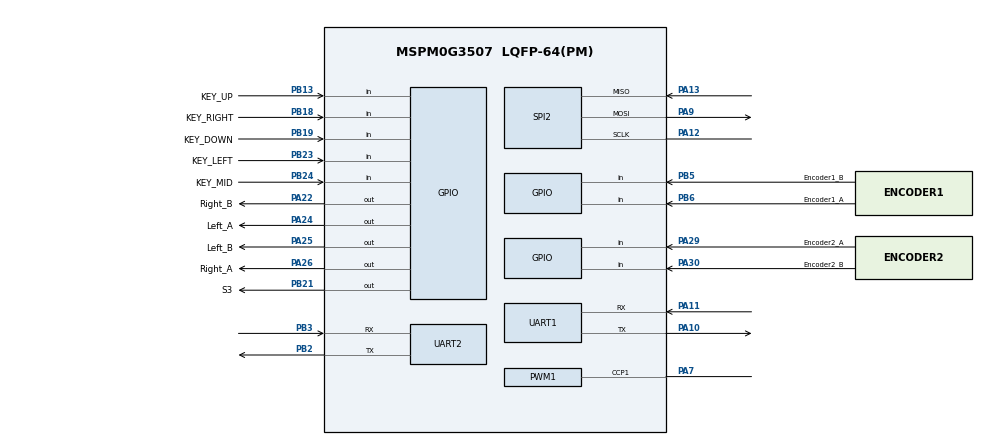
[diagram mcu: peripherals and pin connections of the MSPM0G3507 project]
/**
 * These arguments were used when this file was generated. They will be automatically applied on subsequent loads
 * via the GUI or CLI. Run CLI with '--help' for additional information on how to override these arguments.
 * @cliArgs --device "MSPM0G350X" --part "Default" --package "LQFP-64(PM)" --product "mspm0_sdk@2.02.00.05"
 * @v2CliArgs --device "MSPM0G3507" --package "LQFP-64(PM)" --product "mspm0_sdk@2.02.00.05"
 * @versions {"tool":"1.21.1+3772"}
 */

/**
 * Import the modules used in this configuration.
 */
const ADC12   = scripting.addModule("/ti/driverlib/ADC12", {}, false);
const ADC121  = ADC12.addInstance();
const GPIO    = scripting.addModule("/ti/driverlib/GPIO", {}, false);
const GPIO1   = GPIO.addInstance();
const GPIO2   = GPIO.addInstance();
const GPIO3   = GPIO.addInstance();
const GPIO4   = GPIO.addInstance();
const GPIO5   = GPIO.addInstance();
const GPIO6   = GPIO.addInstance();
const GPIO7   = GPIO.addInstance();
const GPIO8   = GPIO.addInstance();
const PWM     = scripting.addModule("/ti/driverlib/PWM", {}, false);
const PWM1    = PWM.addInstance();
const SPI     = scripting.addModule("/ti/driverlib/SPI", {}, false);
const SPI1    = SPI.addInstance();
const SPI2    = SPI.addInstance();
const SYSCTL  = scripting.addModule("/ti/driverlib/SYSCTL");
const SYSTICK = scripting.addModule("/ti/driverlib/SYSTICK");
const TIMER   = scripting.addModule("/ti/driverlib/TIMER", {}, false);
const TIMER1  = TIMER.addInstance();
const UART    = scripting.addModule("/ti/driverlib/UART", {}, false);
const UART1   = UART.addInstance();
const UART2   = UART.addInstance();
const UART3   = UART.addInstance();

/**
 * Write custom configuration values to the imported modules.
 */
const divider9       = system.clockTree["UDIV"];
divider9.divideValue = 2;

const gate7  = system.clockTree["MFCLKGATE"];
gate7.enable = true;

const multiplier2         = system.clockTree["PLL_QDIV"];
multiplier2.multiplyValue = 4;

const mux4       = system.clockTree["EXHFMUX"];
mux4.inputSelect = "EXHFMUX_XTAL";

const mux8       = system.clockTree["HSCLKMUX"];
mux8.inputSelect = "HSCLKMUX_SYSPLL0";

const mux12       = system.clockTree["SYSPLLMUX"];
mux12.inputSelect = "zSYSPLLMUX_HFCLK";

const pinFunction4       = system.clockTree["HFXT"];
pinFunction4.inputFreq   = 40;
pinFunction4.HFXTStartup = 10;
pinFunction4.enable      = true;

ADC121.$name                             = "ADC_track";
ADC121.sampClkDiv                        = "DL_ADC12_CLOCK_DIVIDE_8";
ADC121.repeatMode                        = true;
ADC121.peripheral.adcPin0.$assign        = "PA27";
ADC121.adcPin0Config.hideOutputInversion = scripting.forceWrite(false);
ADC121.adcPin0Config.$name               = "ti_driverlib_gpio_GPIOPinGeneric2";

const Board = scripting.addModule("/ti/driverlib/Board", {}, false);

GPIO1.$name                               = "KEY";
GPIO1.associatedPins.create(5);
GPIO1.associatedPins[0].internalResistor  = "PULL_UP";
GPIO1.associatedPins[0].interruptEn       = true;
GPIO1.associatedPins[0].direction         = "INPUT";
GPIO1.associatedPins[0].polarity          = "FALL";
GPIO1.associatedPins[0].$name             = "KEY_UP";
GPIO1.associatedPins[0].interruptPriority = "2";
GPIO1.associatedPins[0].pin.$assign       = "PB13";
GPIO1.associatedPins[1].direction         = "INPUT";
GPIO1.associatedPins[1].interruptEn       = true;
GPIO1.associatedPins[1].internalResistor  = "PULL_UP";
GPIO1.associatedPins[1].polarity          = "FALL";
GPIO1.associatedPins[1].$name             = "KEY_DOWN";
GPIO1.associatedPins[1].interruptPriority = "2";
GPIO1.associatedPins[1].pin.$assign       = "PB19";
GPIO1.associatedPins[2].$name             = "KEY_LEFT";
GPIO1.associatedPins[2].direction         = "INPUT";
GPIO1.associatedPins[2].interruptEn       = true;
GPIO1.associatedPins[2].polarity          = "FALL";
GPIO1.associatedPins[2].interruptPriority = "2";
GPIO1.associatedPins[2].pin.$assign       = "PB23";
GPIO1.associatedPins[3].$name             = "KEY_RIGHT";
GPIO1.associatedPins[3].direction         = "INPUT";
GPIO1.associatedPins[3].interruptEn       = true;
GPIO1.associatedPins[3].interruptPriority = "2";
GPIO1.associatedPins[3].polarity          = "FALL";
GPIO1.associatedPins[3].pin.$assign       = "PB18";
GPIO1.associatedPins[4].$name             = "KEY_MID";
GPIO1.associatedPins[4].direction         = "INPUT";
GPIO1.associatedPins[4].interruptEn       = true;
GPIO1.associatedPins[4].interruptPriority = "2";
GPIO1.associatedPins[4].polarity          = "FALL";
GPIO1.associatedPins[4].pin.$assign       = "PB24";

GPIO2.$name                          = "MOTOR_DIR";
GPIO2.associatedPins.create(4);
GPIO2.associatedPins[0].assignedPort = "PORTA";
GPIO2.associatedPins[0].assignedPin  = "24";
GPIO2.associatedPins[0].$name        = "Left_A";
GPIO2.associatedPins[0].initialValue = "SET";
GPIO2.associatedPins[0].pin.$assign  = "PA24";
GPIO2.associatedPins[1].$name        = "Left_B";
GPIO2.associatedPins[1].initialValue = "SET";
GPIO2.associatedPins[1].pin.$assign  = "PA25";
GPIO2.associatedPins[2].$name        = "Right_A";
GPIO2.associatedPins[2].initialValue = "SET";
GPIO2.associatedPins[2].pin.$assign  = "PA26";
GPIO2.associatedPins[3].$name        = "Right_B";
GPIO2.associatedPins[3].initialValue = "SET";
GPIO2.associatedPins[3].pin.$assign  = "PA22";

GPIO3.$name                          = "OLED";
GPIO3.port                           = "PORTB";
GPIO3.associatedPins.create(2);
GPIO3.associatedPins[0].$name        = "SCL";
GPIO3.associatedPins[0].initialValue = "SET";
GPIO3.associatedPins[0].assignedPin  = "9";
GPIO3.associatedPins[1].$name        = "SDA";
GPIO3.associatedPins[1].initialValue = "SET";
GPIO3.associatedPins[1].assignedPin  = "8";

GPIO4.$name                          = "TRACK";
GPIO4.associatedPins.create(3);
GPIO4.associatedPins[0].initialValue = "SET";
GPIO4.associatedPins[0].$name        = "S1";
GPIO4.associatedPins[1].initialValue = "SET";
GPIO4.associatedPins[1].$name        = "S2";
GPIO4.associatedPins[2].$name        = "S3";
GPIO4.associatedPins[2].pin.$assign  = "PB21";

GPIO5.$name                               = "Encoder";
GPIO5.associatedPins.create(4);
GPIO5.associatedPins[0].direction         = "INPUT";
GPIO5.associatedPins[0].interruptEn       = true;
GPIO5.associatedPins[0].polarity          = "RISE";
GPIO5.associatedPins[0].$name             = "Encoder1_A";
GPIO5.associatedPins[0].pin.$assign       = "PB6";
GPIO5.associatedPins[1].direction         = "INPUT";
GPIO5.associatedPins[1].interruptEn       = true;
GPIO5.associatedPins[1].polarity          = "RISE";
GPIO5.associatedPins[1].$name             = "Encoder1_B";
GPIO5.associatedPins[1].interruptPriority = "0";
GPIO5.associatedPins[1].pin.$assign       = "PB5";
GPIO5.associatedPins[2].$name             = "Encoder2_A";
GPIO5.associatedPins[2].direction         = "INPUT";
GPIO5.associatedPins[2].interruptEn       = true;
GPIO5.associatedPins[2].polarity          = "RISE";
GPIO5.associatedPins[2].interruptPriority = "0";
GPIO5.associatedPins[2].pin.$assign       = "PA29";
GPIO5.associatedPins[3].$name             = "Encoder2_B";
GPIO5.associatedPins[3].direction         = "INPUT";
GPIO5.associatedPins[3].interruptEn       = true;
GPIO5.associatedPins[3].polarity          = "RISE";
GPIO5.associatedPins[3].interruptPriority = "0";
GPIO5.associatedPins[3].pin.$assign       = "PA30";

GPIO6.$name                          = "IMU";
GPIO6.associatedPins.create(3);
GPIO6.associatedPins[0].initialValue = "SET";
GPIO6.associatedPins[0].$name        = "IMU_CS";
GPIO6.associatedPins[0].assignedPort = "PORTA";
GPIO6.associatedPins[0].assignedPin  = "8";
GPIO6.associatedPins[1].$name        = "INT1";
GPIO6.associatedPins[1].assignedPort = "PORTB";
GPIO6.associatedPins[1].assignedPin  = "7";
GPIO6.associatedPins[2].$name        = "INT2";
GPIO6.associatedPins[2].assignedPort = "PORTB";
GPIO6.associatedPins[2].assignedPin  = "4";

GPIO7.$name                   = "LCD";
GPIO7.associatedPins.create(3);
GPIO7.associatedPins[0].$name = "LCD_CS";
GPIO7.associatedPins[1].$name = "RST";
GPIO7.associatedPins[2].$name = "DC";

GPIO8.$name                          = "Beep";
GPIO8.associatedPins[0].$name        = "buzzer";
GPIO8.associatedPins[0].assignedPort = "PORTB";
GPIO8.associatedPins[0].assignedPin  = "12";

PWM1.timerStartTimer                    = true;
PWM1.pwmMode                            = "EDGE_ALIGN_UP";
PWM1.$name                              = "PWM_Motor";
PWM1.timerCount                         = 3200;
PWM1.ccIndex                            = [1,3];
PWM1.peripheral.ccp1Pin.$assign         = "PA7";
PWM1.ccp1PinConfig.direction            = scripting.forceWrite("OUTPUT");
PWM1.ccp1PinConfig.hideOutputInversion  = scripting.forceWrite(false);
PWM1.ccp1PinConfig.onlyInternalResistor = scripting.forceWrite(false);
PWM1.ccp1PinConfig.passedPeripheralType = scripting.forceWrite("Digital");
PWM1.ccp1PinConfig.$name                = "ti_driverlib_gpio_GPIOPinGeneric8";
PWM1.PWM_CHANNEL_3.$name                = "ti_driverlib_pwm_PWMTimerCC3";
PWM1.ccp3PinConfig.$name                = "ti_driverlib_gpio_GPIOPinGeneric14";
PWM1.PWM_CHANNEL_1.$name                = "ti_driverlib_pwm_PWMTimerCC0";

SPI1.$name                              = "SPI_LCD";
SPI1.targetBitRate                      = 32000000;
SPI1.frameFormat                        = "MOTO3";
SPI1.direction                          = "PICO";
SPI1.sclkPinConfig.$name                = "ti_driverlib_gpio_GPIOPinGeneric3";
SPI1.sclkPinConfig.direction            = scripting.forceWrite("OUTPUT");
SPI1.sclkPinConfig.onlyInternalResistor = scripting.forceWrite(false);
SPI1.sclkPinConfig.passedPeripheralType = scripting.forceWrite("Digital");
SPI1.mosiPinConfig.$name                = "ti_driverlib_gpio_GPIOPinGeneric4";
SPI1.mosiPinConfig.direction            = scripting.forceWrite("OUTPUT");
SPI1.mosiPinConfig.hideOutputInversion  = scripting.forceWrite(false);
SPI1.mosiPinConfig.onlyInternalResistor = scripting.forceWrite(false);
SPI1.mosiPinConfig.passedPeripheralType = scripting.forceWrite("Digital");

SPI2.$name                              = "SPI_IMU";
SPI2.enableDMAEvent1                    = false;
SPI2.enableDMAEvent2                    = false;
SPI2.targetBitRate                      = 5000000;
SPI2.peripheral.sclkPin.$assign         = "PA12";
SPI2.peripheral.mosiPin.$assign         = "PA9";
SPI2.peripheral.misoPin.$assign         = "PA13";
SPI2.sclkPinConfig.direction            = scripting.forceWrite("OUTPUT");
SPI2.sclkPinConfig.onlyInternalResistor = scripting.forceWrite(false);
SPI2.sclkPinConfig.passedPeripheralType = scripting.forceWrite("Digital");
SPI2.sclkPinConfig.$name                = "ti_driverlib_gpio_GPIOPinGeneric11";
SPI2.mosiPinConfig.direction            = scripting.forceWrite("OUTPUT");
SPI2.mosiPinConfig.hideOutputInversion  = scripting.forceWrite(false);
SPI2.mosiPinConfig.onlyInternalResistor = scripting.forceWrite(false);
SPI2.mosiPinConfig.passedPeripheralType = scripting.forceWrite("Digital");
SPI2.mosiPinConfig.$name                = "ti_driverlib_gpio_GPIOPinGeneric12";
SPI2.misoPinConfig.onlyInternalResistor = scripting.forceWrite(false);
SPI2.misoPinConfig.passedPeripheralType = scripting.forceWrite("Digital");
SPI2.misoPinConfig.$name                = "ti_driverlib_gpio_GPIOPinGeneric13";
SPI2.cs0PinConfig.direction             = scripting.forceWrite("OUTPUT");
SPI2.cs0PinConfig.hideOutputInversion   = scripting.forceWrite(false);
SPI2.cs0PinConfig.onlyInternalResistor  = scripting.forceWrite(false);
SPI2.cs0PinConfig.passedPeripheralType  = scripting.forceWrite("Digital");
SPI2.cs0PinConfig.$name                 = "ti_driverlib_gpio_GPIOPinGeneric9";

SYSCTL.forceDefaultClkConfig = true;
SYSCTL.clockTreeEn           = true;

SYSTICK.periodEnable      = true;
SYSTICK.period            = 32000;
SYSTICK.interruptEnable   = true;
SYSTICK.interruptPriority = "0";
SYSTICK.systickEnable     = true;

TIMER1.$name            = "TIMER_0";
TIMER1.timerClkDiv      = 8;
TIMER1.timerClkPrescale = 100;
TIMER1.timerMode        = "PERIODIC_UP";
TIMER1.timerStartTimer  = true;
TIMER1.interrupts       = ["LOAD"];
TIMER1.timerPeriod      = "1ms";

UART1.enabledInterrupts                = ["RX"];
UART1.targetBaudRate                   = 115200;
UART1.$name                            = "UART_debug";
UART1.peripheral.$assign               = "UART0";
UART1.peripheral.rxPin.$assign         = "PA11";
UART1.peripheral.txPin.$assign         = "PA10";
UART1.txPinConfig.direction            = scripting.forceWrite("OUTPUT");
UART1.txPinConfig.hideOutputInversion  = scripting.forceWrite(false);
UART1.txPinConfig.onlyInternalResistor = scripting.forceWrite(false);
UART1.txPinConfig.passedPeripheralType = scripting.forceWrite("Digital");
UART1.txPinConfig.$name                = "ti_driverlib_gpio_GPIOPinGeneric0";
UART1.rxPinConfig.hideOutputInversion  = scripting.forceWrite(false);
UART1.rxPinConfig.onlyInternalResistor = scripting.forceWrite(false);
UART1.rxPinConfig.passedPeripheralType = scripting.forceWrite("Digital");
UART1.rxPinConfig.$name                = "ti_driverlib_gpio_GPIOPinGeneric1";

UART2.$name                    = "UART_1";
UART2.peripheral.rxPin.$assign = "PB3";
UART2.peripheral.txPin.$assign = "PB2";
UART2.txPinConfig.$name        = "ti_driverlib_gpio_GPIOPinGeneric5";
UART2.rxPinConfig.$name        = "ti_driverlib_gpio_GPIOPinGeneric6";

UART3.$name             = "UART_2";
UART3.targetBaudRate    = 115200;
UART3.txPinConfig.$name = "ti_driverlib_gpio_GPIOPinGeneric15";
UART3.rxPinConfig.$name = "ti_driverlib_gpio_GPIOPinGeneric16";

/**
 * Pinmux solution for unlocked pins/peripherals. This ensures that minor changes to the automatic solver in a future
 * version of the tool will not impact the pinmux you originally saw.  These lines can be completely deleted in order to
 * re-solve from scratch.
 */
pinFunction4.peripheral.$suggestSolution           = "SYSCTL";
pinFunction4.peripheral.hfxInPin.$suggestSolution  = "PA5";
pinFunction4.peripheral.hfxOutPin.$suggestSolution = "PA6";
ADC121.peripheral.$suggestSolution                 = "ADC0";
Board.peripheral.$suggestSolution                  = "DEBUGSS";
Board.peripheral.swclkPin.$suggestSolution         = "PA20";
Board.peripheral.swdioPin.$suggestSolution         = "PA19";
GPIO3.associatedPins[0].pin.$suggestSolution       = "PB9";
GPIO3.associatedPins[1].pin.$suggestSolution       = "PB8";
GPIO4.associatedPins[0].pin.$suggestSolution       = "PB14";
GPIO4.associatedPins[1].pin.$suggestSolution       = "PA14";
GPIO6.associatedPins[0].pin.$suggestSolution       = "PA8";
GPIO6.associatedPins[1].pin.$suggestSolution       = "PB7";
GPIO6.associatedPins[2].pin.$suggestSolution       = "PB4";
GPIO7.associatedPins[0].pin.$suggestSolution       = "PA15";
GPIO7.associatedPins[1].pin.$suggestSolution       = "PA16";
GPIO7.associatedPins[2].pin.$suggestSolution       = "PB17";
GPIO8.associatedPins[0].pin.$suggestSolution       = "PB12";
PWM1.peripheral.$suggestSolution                   = "TIMA0";
PWM1.peripheral.ccp3Pin.$suggestSolution           = "PA23";
SPI1.peripheral.$suggestSolution                   = "SPI1";
SPI1.peripheral.sclkPin.$suggestSolution           = "PB16";
SPI1.peripheral.mosiPin.$suggestSolution           = "PB15";
SPI2.peripheral.$suggestSolution                   = "SPI0";
SPI2.peripheral.cs0Pin.$suggestSolution            = "PA2";
TIMER1.peripheral.$suggestSolution                 = "TIMA1";
UART2.peripheral.$suggestSolution                  = "UART3";
UART3.peripheral.$suggestSolution                  = "UART1";
UART3.peripheral.rxPin.$suggestSolution            = "PA18";
UART3.peripheral.txPin.$suggestSolution            = "PA17";
